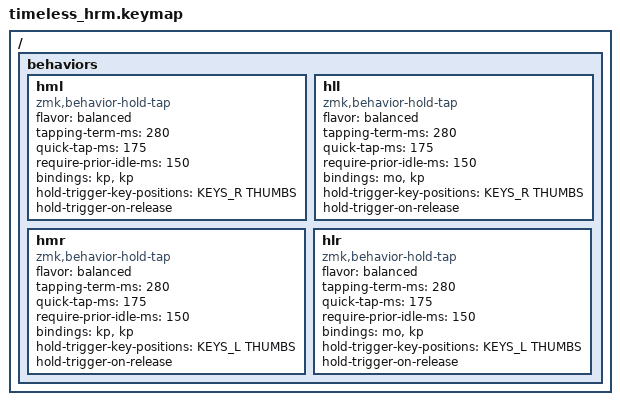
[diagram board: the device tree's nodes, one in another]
#include "zmk-helpers/helper.h"
#include "zmk-helpers/key-labels/36.h"                                      // Source key-labels.
#define KEYS_L LT0 LT1 LT2 LT3 LT4 LM0 LM1 LM2 LM3 LM4 LB0 LB1 LB2 LB3 LB4  // Left-hand keys.
#define KEYS_R RT0 RT1 RT2 RT3 RT4 RM0 RM1 RM2 RM3 RM4 RB0 RB1 RB2 RB3 RB4  // Right-hand keys.
#define THUMBS LH2 LH1 LH0 RH0 RH1 RH2                                      // Thumb keys.

/* Left-hand HRMs. */
ZMK_HOLD_TAP(hml,
    flavor = "balanced";
    tapping-term-ms = <280>;
    quick-tap-ms = <175>;
    require-prior-idle-ms = <150>;
    bindings = <&kp>, <&kp>;
    hold-trigger-key-positions = <KEYS_R THUMBS>;
    hold-trigger-on-release;
)

/* Left-pinky momentary layer mod. */
ZMK_HOLD_TAP(hll,
    flavor = "balanced";
    tapping-term-ms = <280>;
    quick-tap-ms = <175>;
    require-prior-idle-ms = <150>;
    bindings = <&mo>, <&kp>;
    hold-trigger-key-positions = <KEYS_R THUMBS>;
    hold-trigger-on-release;
)

/* Right-hand HRMs. */
ZMK_HOLD_TAP(hmr,
    flavor = "balanced";
    tapping-term-ms = <280>;
    quick-tap-ms = <175>;
    require-prior-idle-ms = <150>;
    bindings = <&kp>, <&kp>;
    hold-trigger-key-positions = <KEYS_L THUMBS>;
    hold-trigger-on-release;
)


/* Right-pinky momentary layer mod. */
ZMK_HOLD_TAP(hlr,
    flavor = "balanced";
    tapping-term-ms = <280>;
    quick-tap-ms = <175>;
    require-prior-idle-ms = <150>;
    bindings = <&mo>, <&kp>;
    hold-trigger-key-positions = <KEYS_L THUMBS>;
    hold-trigger-on-release;
)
